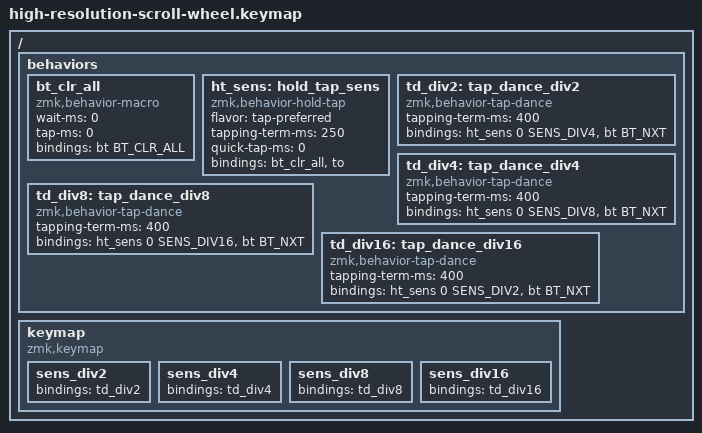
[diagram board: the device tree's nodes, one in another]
#include <behaviors.dtsi>
#include <dt-bindings/zmk/keys.h>
#include <dt-bindings/zmk/bt.h>
#include <dt-bindings/zmk/pointing.h>
#include <dt-bindings/zmk/outputs.h>

#define SENS_DIV2 0
#define SENS_DIV4 1
#define SENS_DIV8 2
#define SENS_DIV16 3

/ {
    behaviors {
        bt_clr_all: bt_clr_all {
            compatible = "zmk,behavior-macro";
            wait-ms = <0>;
            tap-ms = <0>;
            #binding-cells = <0>;
            bindings = <&bt BT_CLR_ALL>;
        };

        ht_sens: hold_tap_sens {
            compatible = "zmk,behavior-hold-tap";
            #binding-cells = <2>;
            flavor = "tap-preferred";
            tapping-term-ms = <250>;
            quick-tap-ms = <0>;
            bindings = <&bt_clr_all>, <&to>;
        };

        td_div2: tap_dance_div2 {
            compatible = "zmk,behavior-tap-dance";
            #binding-cells = <0>;
            tapping-term-ms = <400>;
            bindings = <&ht_sens 0 SENS_DIV4>, <&bt BT_NXT>;
        };

        td_div4: tap_dance_div4 {
            compatible = "zmk,behavior-tap-dance";
            #binding-cells = <0>;
            tapping-term-ms = <400>;
            bindings = <&ht_sens 0 SENS_DIV8>, <&bt BT_NXT>;
        };

        td_div8: tap_dance_div8 {
            compatible = "zmk,behavior-tap-dance";
            #binding-cells = <0>;
            tapping-term-ms = <400>;
            bindings = <&ht_sens 0 SENS_DIV16>, <&bt BT_NXT>;
        };

        td_div16: tap_dance_div16 {
            compatible = "zmk,behavior-tap-dance";
            #binding-cells = <0>;
            tapping-term-ms = <400>;
            bindings = <&ht_sens 0 SENS_DIV2>, <&bt BT_NXT>;
        };
    };
    
    keymap {
        compatible = "zmk,keymap";

        sens_div2 {
            bindings = <
                &td_div2
            >;
        };

        sens_div4 {
            bindings = <
                &td_div4
            >;
        };

        sens_div8 {
            bindings = <
                &td_div8
            >;
        };

        sens_div16 {
            bindings = <
                &td_div16
            >;
        };
    };
};
